VERSION "HINBNNNYYNNNYYNNNNNNNNNNNNYNNNYYYNNYNNNNNN/4//%%/4/'%**4NNN///"

NS_ :

BS_:

BU_: SteeringServo_Rear SteeringServo_Front VMU
VAL_TABLE_ Wire_Isolation_Status 6 "Isolation failure flag (filtered & unfiltered)" 5 "Isolation failure flag (unfiltered) & reserved" 4 "Isolation failure flag (unfiltered)" 3 "Isolation failure flag & reserved" 2 "Isolation failure flag" 1 "reserved" 0 "ok" ;
VAL_TABLE_ DeviceStatus 15 "Overheat & Warning & Failure & Operating" 14 "Overheat & Warning & Failure" 13 "Overheat & Warning & Operating" 12 "Overheat & Warning" 11 "Overheat & Failure & Operating" 10 "Overheat & Failure" 9 "Overheat & Operating" 8 "Overheat" 7 "Warning & Failure & Operating" 6 "Warning & Failure" 5 "Warning & Operating" 4 "Warning" 3 "Failure & Operating" 2 "Failure" 1 "Operating" 0 "Idle" ;
VAL_TABLE_ Enable 1 "Enable" 0 "Disable" ;
VAL_TABLE_ Heartbeat_State 127 "PreOperational" 5 "Operational" 4 "Stopped" 0 "Bootup" ;

BO_ 3221225472 VECTOR__INDEPENDENT_SIG_MSG: 0 Vector__XXX
 SG_ ServoTomsk_current : 0|16@1- (0.01,0) [-327.68|327.67] "A" Vector__XXX
 SG_ ServoOld_current : 0|16@1- (0.001,0) [-32.768|32.767] "A" Vector__XXX
 SG_ ServoTomsk_current : 0|16@1- (0.01,0) [-327.68|327.67] "A" Vector__XXX
 SG_ ServoOld_current : 0|16@1- (0.001,0) [-32.768|32.767] "A" Vector__XXX

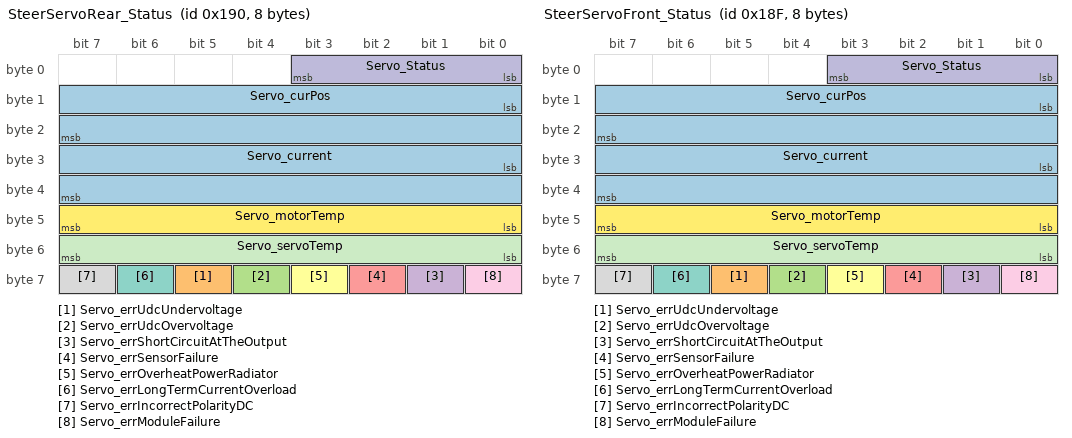
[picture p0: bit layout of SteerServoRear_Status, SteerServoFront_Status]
BO_ 400 SteerServoRear_Status: 8 SteeringServo_Rear
 SG_ Servo_current : 24|16@1- (0.01,0) [-327.68|327.67] "A" Vector__XXX
 SG_ Servo_errUdcUndervoltage : 61|1@1+ (1,0) [0|1] "" Vector__XXX
 SG_ Servo_errUdcOvervoltage : 60|1@1+ (1,0) [0|1] "" Vector__XXX
 SG_ Servo_errShortCircuitAtTheOutput : 57|1@1+ (1,0) [0|1] "" Vector__XXX
 SG_ Servo_errSensorFailure : 58|1@1+ (1,0) [0|1] "" Vector__XXX
 SG_ Servo_errOverheatPowerRadiator : 59|1@1+ (1,0) [0|1] "" Vector__XXX
 SG_ Servo_errLongTermCurrentOverload : 62|1@1+ (1,0) [0|1] "" Vector__XXX
 SG_ Servo_errIncorrectPolarityDC : 63|1@1+ (1,0) [0|1] "" Vector__XXX
 SG_ Servo_errModuleFailure : 56|1@1+ (1,0) [0|1] "" Vector__XXX
 SG_ Servo_Status : 0|4@1+ (1,0) [0|15] ""  VMU
 SG_ Servo_servoTemp : 48|8@1+ (1,-40) [-40|215] "°C"  VMU
 SG_ Servo_motorTemp : 40|8@1+ (1,-40) [-40|215] "°C"  VMU
 SG_ Servo_curPos : 8|16@1- (1,0) [-32768|32767] ""  VMU

BO_ 399 SteerServoFront_Status: 8 SteeringServo_Front
 SG_ Servo_current : 24|16@1- (0.01,0) [-327.68|327.67] "A" Vector__XXX
 SG_ Servo_errUdcUndervoltage : 61|1@1+ (1,0) [0|1] "" Vector__XXX
 SG_ Servo_errUdcOvervoltage : 60|1@1+ (1,0) [0|1] "" Vector__XXX
 SG_ Servo_errShortCircuitAtTheOutput : 57|1@1+ (1,0) [0|1] "" Vector__XXX
 SG_ Servo_errSensorFailure : 58|1@1+ (1,0) [0|1] "" Vector__XXX
 SG_ Servo_errOverheatPowerRadiator : 59|1@1+ (1,0) [0|1] "" Vector__XXX
 SG_ Servo_errLongTermCurrentOverload : 62|1@1+ (1,0) [0|1] "" Vector__XXX
 SG_ Servo_errIncorrectPolarityDC : 63|1@1+ (1,0) [0|1] "" Vector__XXX
 SG_ Servo_errModuleFailure : 56|1@1+ (1,0) [0|1] "" Vector__XXX
 SG_ Servo_Status : 0|4@1+ (1,0) [0|15] ""  VMU
 SG_ Servo_servoTemp : 48|8@1+ (1,-40) [-40|215] "°C"  VMU
 SG_ Servo_motorTemp : 40|8@1+ (1,-40) [-40|215] "°C"  VMU
 SG_ Servo_curPos : 8|16@1- (1,0) [-32768|32767] ""  VMU

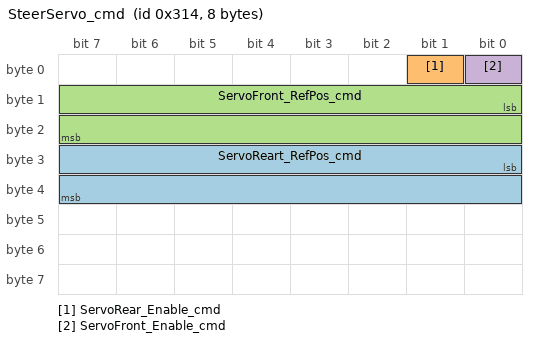
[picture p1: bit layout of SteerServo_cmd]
BO_ 788 SteerServo_cmd: 8 VMU
 SG_ ServoReart_RefPos_cmd : 24|16@1- (1,0) [-1000|1000] ""  SteeringServo_Rear
 SG_ ServoRear_Enable_cmd : 1|1@1+ (1,0) [0|1] ""  SteeringServo_Rear
 SG_ ServoFront_RefPos_cmd : 8|16@1- (1,0) [-1000|1000] ""  SteeringServo_Front
 SG_ ServoFront_Enable_cmd : 0|1@1+ (1,0) [0|1] ""  SteeringServo_Front

BO_ 1812 VMU_Heartbeat: 1 VMU
 SG_ Toggle : 7|1@1+ (1,0) [0|1] "" Vector__XXX
 SG_ State : 0|7@1+ (1,0) [0|127] "" Vector__XXX

CM_ BO_ 3221225472 "This is a message for not used signals, created by Vector CANdb++ DBC OLE DB Provider.";
BA_DEF_ SG_  "GenSigStartValue" INT 0 0;
BA_DEF_ BO_  "CO_MsgCategory" INT 0 0;
BA_DEF_  "CO_MsgColourSupported" INT 0 1;
BA_DEF_  "CANopenApplProfile" INT 0 0;
BA_DEF_  "ProtocolType" STRING ;
BA_DEF_DEF_  "GenSigStartValue" 0;
BA_DEF_DEF_  "CO_MsgCategory" 0;
BA_DEF_DEF_  "CO_MsgColourSupported" 1;
BA_DEF_DEF_  "CANopenApplProfile" 301;
BA_DEF_DEF_  "ProtocolType" "CANopen";
BA_ "CO_MsgCategory" BO_ 1812 505;
BA_ "GenSigStartValue" SG_ 400 Servo_servoTemp 40;
BA_ "GenSigStartValue" SG_ 400 Servo_motorTemp 40;
BA_ "GenSigStartValue" SG_ 399 Servo_servoTemp 40;
BA_ "GenSigStartValue" SG_ 399 Servo_motorTemp 40;
VAL_ 400 Servo_Status 15 "Overheat & Warning & Failure & Operating" 14 "Overheat & Warning & Failure" 13 "Overheat & Warning & Operating" 12 "Overheat & Warning" 11 "Overheat & Failure & Operating" 10 "Overheat & Failure" 9 "Overheat & Operating" 8 "Overheat" 7 "Warning & Failure & Operating" 6 "Warning & Failure" 5 "Warning & Operating" 4 "Warning" 3 "Failure & Operating" 2 "Failure" 1 "Operating" 0 "Idle" ;
VAL_ 399 Servo_Status 15 "Overheat & Warning & Failure & Operating" 14 "Overheat & Warning & Failure" 13 "Overheat & Warning & Operating" 12 "Overheat & Warning" 11 "Overheat & Failure & Operating" 10 "Overheat & Failure" 9 "Overheat & Operating" 8 "Overheat" 7 "Warning & Failure & Operating" 6 "Warning & Failure" 5 "Warning & Operating" 4 "Warning" 3 "Failure & Operating" 2 "Failure" 1 "Operating" 0 "Idle" ;
VAL_ 788 ServoRear_Enable_cmd 1 "Enable" 0 "Disable" ;
VAL_ 788 ServoFront_Enable_cmd 1 "Enable" 0 "Disable" ;
VAL_ 1812 State 127 "PreOperational" 5 "Operational" 4 "Stopped" 0 "Bootup" ;
